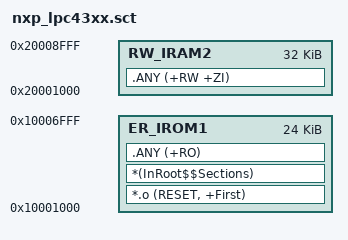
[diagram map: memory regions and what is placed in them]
; *************************************************************
; *** Scatter-Loading Description File generated by uVision ***
; *************************************************************

LR_IROM1 0x10001000 0x00006000  {    ; load region size_region
  ER_IROM1 0x10001000 0x00006000  {  ; load address = execution address
   *.o (RESET, +First)
   *(InRoot$$Sections)
   .ANY (+RO)
  }
  RW_IRAM2 0x20001000 0x00008000  {  ; RW data
   .ANY (+RW +ZI)
  }
}

